# PY32MD310xx register map
Vendor: Puya; Series: PY32M; File version: 1.0.0
Arm 32-bit Cortex-M0+ Microcontroller based device, CPU clock up to 48 MHz.
CPU: CM0+ r0p1, little endian, no MPU, no FPU, 4 interrupt priority bits
Registers are 32-bit, read-write, reset 0x0 unless marked. A register's access mark holds for its fields unless they carry their own. Offsets are from the block's base; lines under a group give offsets from that group; [hi:lo] are bit positions; {n}, {i} and the like mark numbered series; 'fields as' and 'values as' point back to an identical list; <NAME> marks a mode.

## Memory map
0x40000400 TIM3 size 0x400 — General purpose timer
0x40002000 TIM14 size 0x400 — General purpose timer
0x40002400 LED size 0x400 — LED CONTROLLER
0x40002800 RTC size 0x400 — Real time clock
0x40002C00 WWDG size 0x400 — Window watchdog
0x40003000 IWDG size 0x400 — Independent watchdog
0x40003800 SPI2 size 0x400
0x40004400 USART2 size 0x400
0x40005400 I2C size 0x400 — Inter integrated circuit
0x40007000 PWR size 0x400 — Power control
0x40007C00 LPTIM size 0x400 — Low power timer
0x40010000 SYSCFG size 0x30 — System configuration controller
0x40010200 COMP1 size 0x10 — Comparator
0x40010210 COMP2 size 0x10 — Comparator
0x40012400 ADC size 0x400 — Analog to Digital Converter
0x40012C00 TIM1 size 0x400 — Advanced timer
0x40013000 SPI1 size 0x400 — Serial peripheral interface
0x40013800 USART1 size 0x400 — Universal synchronous asynchronous receivertransmitter
0x40014400 TIM16 size 0x400 — General purpose timer
0x40014800 TIM17 size 0x400
0x40015800 DBGMCU size 0x400 — Debug support
0x40020000 DMA size 0x400 — Direct memory access
0x40021000 RCC size 0x400 — Reset and clock control
0x40021800 EXTI size 0x400 — External interrupt/eventcontroller
0x40022000 FLASH size 0x400
0x40023000 CRC size 0x400 — CRC calculation unit
0x50000000 GPIOA size 0x400 — General-purpose I/Os
0x50000400 GPIOB size 0x400 — General-purpose I/Os
0x50001400 GPIOF size 0x400

## Interrupts
0 WWDG — Window WatchDog Interrupt
1 PVD (EXTI) — PVD Interrupt through EXTI Lines 16
2 RTC — RTC Interrupt through EXTI Lines 19
3 FLASH — FLASH global Interrupt
4 RCC — RCC global Interrupt
5 EXTI0_1 (EXTI) — EXTI Line 0 and 1 Interrupt
6 EXTI2_3 (EXTI) — EXTI Line 2 and 3 Interrupt
7 EXTI4_15 (EXTI) — EXTI Line 4 to 15 Interrupt
9 DMA_Channel1 (DMA) — DMA Channel 1 Interrupt
10 DMA_Channel2_3 (DMA) — DMA Channel 2 and Channel 3 Interrupt
12 ADC_COMP (ADC) — ADC and COMP Interrupt through EXTI Lines 17 and 18
13 TIM1_BRK_UP_TRG_COM (TIM1) — TIM1 Break, Update, Trigger and Commutation Interrupt
14 TIM1_CC (TIM1) — TIM1 Capture Compare Interrupt
16 TIM3 — TIM3 global Interrupt
19 TIM14 — TIM14 global Interrupt
21 TIM16 — TIM16 global Interrupt
22 TIM17 — TIM17 global Interrupt
23 I2C1 (I2C) — I2C1 global Interrupt
25 SPI1 — SPI1 global Interrupt
26 SPI2 — SPI2 global Interrupt
27 USART1 — USART1 global Interrupt
28 USART2 — USART2 global Interrupt
30 LED — LED global Interrupt

## ADC — Analog to Digital Converter
Base 0x40012400
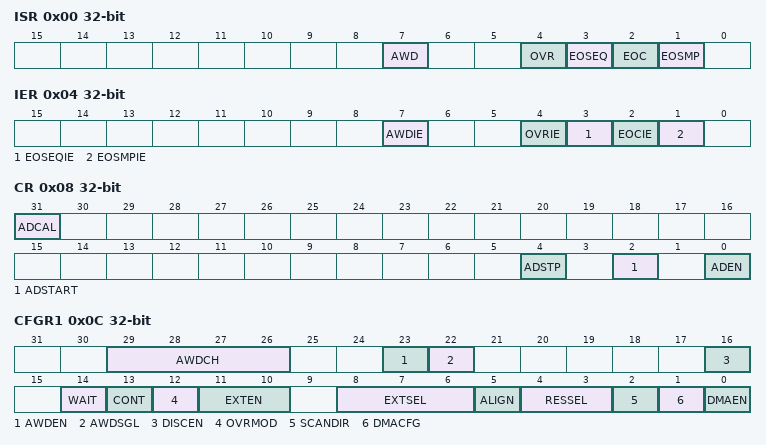
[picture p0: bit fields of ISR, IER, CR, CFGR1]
0x00 ISR — ADC interrupt and status register
  [7] AWD — ADC analog watchdog flag
  [4] OVR — ADC group regular overrunflag
  [3] EOSEQ — ADC group regular end of sequenceconversions flag
  [2] EOC — ADC group regular end of unitaryconversion flag
  [1] EOSMP — ADC group regular end of samplingflag
0x04 IER — ADC interrupt enable register
  [7] AWDIE — ADC analog watchdoginterrupt
  [4] OVRIE — ADC group regular overruninterrupt
  [3] EOSEQIE — ADC group regular end of sequenceconversions interrupt
  [2] EOCIE — ADC group regular end of unitaryconversion interrupt
  [1] EOSMPIE — ADC group regular end of samplinginterrupt
0x08 CR — ADC control register
  [31] ADCAL — ADC group regular conversioncalibration
  [4] ADSTP — ADC group regular conversionstop
  [2] ADSTART — ADC group regular conversionstart
  [0] ADEN — ADC enable
0x0C CFGR1 — ADC configuration register 1
  [29:26] AWDCH — ADC analog watchdog monitored channelselection
    1=0; 2=1; 4=2; 8=3
  [23] AWDEN — ADC analog watchdog enable on scopeADC group regular
  [22] AWDSGL — ADC analog watchdog monitoring asingle channel or all channels
  [16] DISCEN — ADC group regular sequencerdiscontinuous mode
  [14] WAIT — Wait conversion mode
  [13] CONT — ADC group regular continuous conversionmode
  [12] OVRMOD — ADC group regular overrunconfiguration
  [11:10] EXTEN — ADC group regular external triggerpolarity
    1=0; 2=1
  [8:6] EXTSEL — ADC group regular external triggersource
    1=0; 2=1; 4=2
  [5] ALIGN — ADC data alignement
  [4:3] RESSEL — ADC data resolution
    1=0; 2=1
  [2] SCANDIR — Scan sequence direction
  [1] DMACFG — ADC DMA transferconfiguration
  [0] DMAEN — ADC DMA transfer enable
0x10 CFGR2 — ADC configuration register 2
  [31:28] CKMODE — ADC clock mode
    1=0; 2=1; 4=2; 8=3
0x14 SMPR — ADC sampling time register
  [2:0] SMP — Sampling time selection
    1=0; 2=1; 4=2
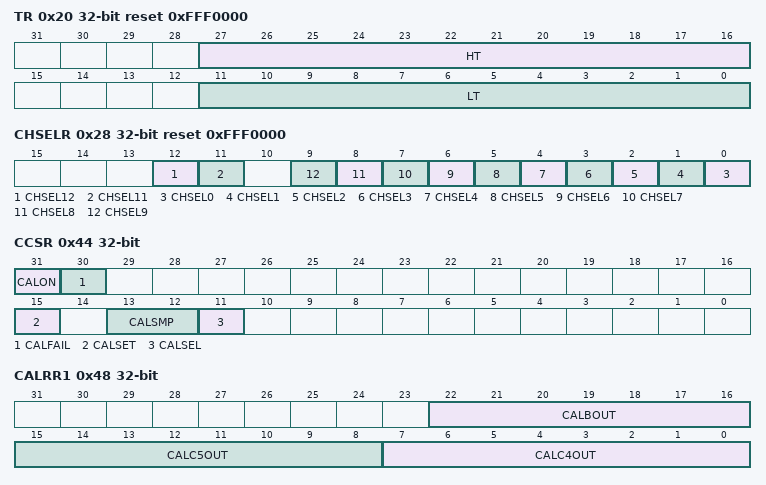
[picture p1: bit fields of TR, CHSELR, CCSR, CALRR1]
0x20 TR reset 0xFFF0000 — ADC analog watchdog 1 threshold register
  [27:16] HT — ADC analog watchdog thresholdhigh
    1=0; 2=1; 4=2; 8=3; 16=4; 32=5; 64=6; 128=7; 0x100=8; 0x200=9; 0x400=10; 0x800=11
  [11:0] LT — ADC analog watchdog thresholdlow
    values as HT
0x28 CHSELR reset 0xFFF0000 — ADC group regular sequencer register
  [12] CHSEL12 — Channel-12 selection
  [11] CHSEL11 — Channel-11 selection
  [n] CHSEL{n} (n=0..9) — Channel-{n} selection
0x40 DR ro — ADC group regular data register
  [15:0] DATA — ADC group regular conversiondata
    1=0; 2=1; 4=2; 8=3; 16=4; 32=5; 64=6; 128=7; 0x100=8; 0x200=9; 0x400=10; 0x800=11; 0x1000=12; 0x2000=13; 0x4000=14; 0x8000=15
0x44 CCSR — ADC calibration configuration and status register
  [31] CALON ro — Calibration flag
  [30] CALFAIL — Calibration fail flag
  [15] CALSET — Calibration factor selection
  [13:12] CALSMP — Calibration sample time selection
    1=0; 2=1
  [11] CALSEL — Calibration contents selection
0x48 CALRR1 ro — ADC calibration result register 1
  [22:16] CALBOUT — offset result
  [15:8] CALC5OUT — C5 result
  [7:0] CALC4OUT — C4 result
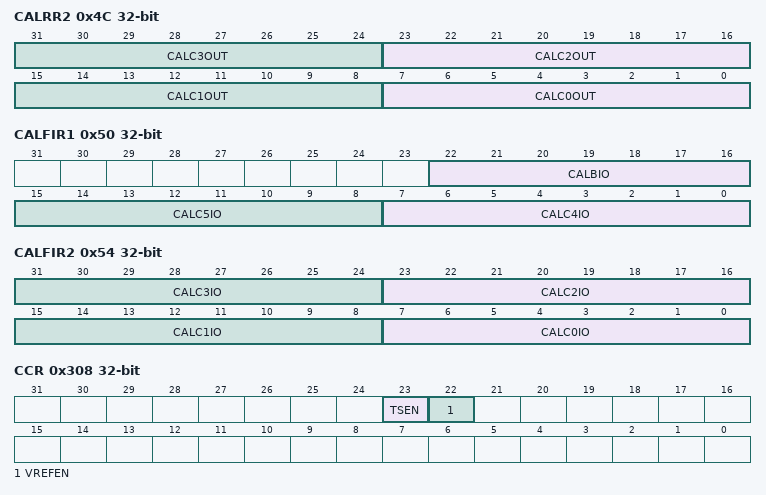
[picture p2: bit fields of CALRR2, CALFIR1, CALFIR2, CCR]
0x4C CALRR2 ro — ADC calibration result register 2
  [8n+7:8n] CALC{n}OUT (n=0..3) — C{n} result
0x50 CALFIR1 — ADC calibration factor input register 1
  [22:16] CALBIO — Calibration offset factor input
  [15:8] CALC5IO — Calibration C5 factor input
  [7:0] CALC4IO — Calibration C4 factor input
0x54 CALFIR2 — ADC calibration factor input register 2
  [8n+7:8n] CALC{n}IO (n=0..3) — Calibration C{n} factor input
0x308 CCR — ADC common configuration register
  [23] TSEN — Temperature sensor enable
  [22] VREFEN — VREFINT enable
